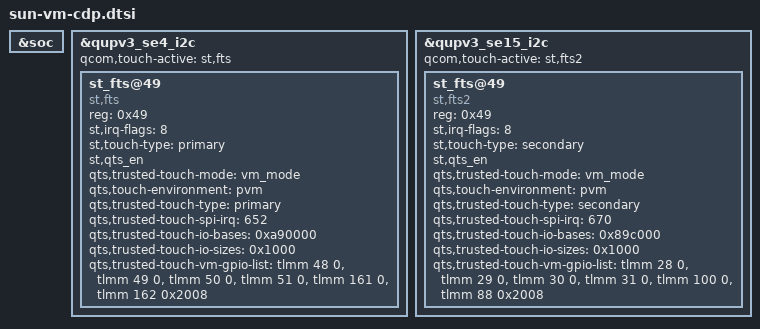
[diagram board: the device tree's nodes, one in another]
// SPDX-License-Identifier: BSD-3-Clause
/*
 * Copyright (c) 2023-2024 Qualcomm Innovation Center, Inc. All rights reserved.
 */
&soc {
};

&qupv3_se4_i2c {
	status = "ok";
	qcom,touch-active = "st,fts";

	st_fts@49 {
		compatible = "st,fts";
		reg = <0x49>;
		st,irq-flags = <8>;

		st,touch-type = "primary";
		st,qts_en;
		qts,trusted-touch-mode = "vm_mode";
		qts,touch-environment = "pvm";
		qts,trusted-touch-type = "primary";
		qts,trusted-touch-spi-irq = <652>;
		qts,trusted-touch-io-bases = <0xa90000>;
		qts,trusted-touch-io-sizes = <0x1000>;
		qts,trusted-touch-vm-gpio-list = <&tlmm 48 0 &tlmm 49 0 &tlmm 50 0
						&tlmm 51 0 &tlmm 161 0 &tlmm 162 0x2008>;
	};
};

&qupv3_se15_i2c {
	status = "ok";
	qcom,touch-active = "st,fts2";

	st_fts@49 {
		compatible = "st,fts2";
		reg = <0x49>;
		st,irq-flags = <8>;

		st,touch-type = "secondary";
		st,qts_en;
		qts,trusted-touch-mode = "vm_mode";
		qts,touch-environment = "pvm";
		qts,trusted-touch-type = "secondary";
		qts,trusted-touch-spi-irq = <670>;
		qts,trusted-touch-io-bases = <0x89c000>;
		qts,trusted-touch-io-sizes = <0x1000>;
		qts,trusted-touch-vm-gpio-list = <&tlmm 28 0 &tlmm 29 0 &tlmm 30 0
						&tlmm 31 0 &tlmm 100 0 &tlmm 88 0x2008>;
	};
};
